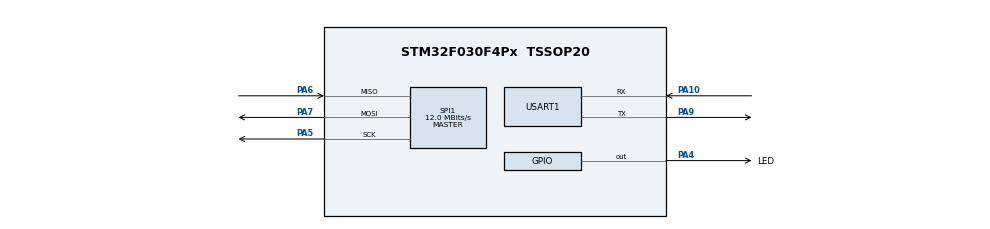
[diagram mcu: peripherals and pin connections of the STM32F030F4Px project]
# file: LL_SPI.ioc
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Mcu.Family=STM32F0
Mcu.Name=STM32F030F4Px
Mcu.Package=TSSOP20
PA10.Mode=Asynchronous
PA10.Signal=USART1_RX
PA13.Mode=Serial_Wire
PA13.Signal=SYS_SWDIO
PA14.Mode=Serial_Wire
PA14.Signal=SYS_SWCLK
PA4.GPIO_Label=LED
PA4.Signal=GPIO_Output
PA5.Mode=Full_Duplex_Master
PA5.Signal=SPI1_SCK
PA6.Mode=Full_Duplex_Master
PA6.Signal=SPI1_MISO
PA7.Mode=Full_Duplex_Master
PA7.Signal=SPI1_MOSI
PA9.Mode=Asynchronous
PA9.Signal=USART1_TX
PF0-OSC_IN.Mode=HSE-External-Oscillator
PF0-OSC_IN.Signal=RCC_OSC_IN
PF1-OSC_OUT.Mode=HSE-External-Oscillator
PF1-OSC_OUT.Signal=RCC_OSC_OUT
ProjectManager.HeapSize=0x200
ProjectManager.StackSize=0x400
ProjectManager.TargetToolchain=EWARM
RCC.AHBFreq_Value=48000000
RCC.APB1Freq_Value=48000000
RCC.APB1TimFreq_Value=48000000
RCC.HCLKFreq_Value=48000000
RCC.PLLMUL=RCC_PLL_MUL12
RCC.SYSCLKFreq_VALUE=48000000
RCC.SYSCLKSource=RCC_SYSCLKSOURCE_PLLCLK
SPI1.BaudRatePrescaler=SPI_BAUDRATEPRESCALER_4
SPI1.CLKPhase=SPI_PHASE_2EDGE
SPI1.CLKPolarity=SPI_POLARITY_HIGH
SPI1.CalculateBaudRate=12.0 MBits/s
SPI1.DataSize=SPI_DATASIZE_16BIT
SPI1.Direction=SPI_DIRECTION_2LINES
SPI1.Mode=SPI_MODE_MASTER
SPI1.VirtualType=VM_MASTER
USART1.VirtualMode-Asynchronous=VM_ASYNC
board=LL_SPI

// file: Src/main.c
/**
  ******************************************************************************
  * @file           : main.c
  * @brief          : Main program body
  ******************************************************************************
  ** This notice applies to any and all portions of this file
  * that are not between comment pairs USER CODE BEGIN and
  * USER CODE END. Other portions of this file, whether
  * inserted by the user or by software development tools
  * are owned by their respective copyright owners.
  *
  * COPYRIGHT(c) 2018 STMicroelectronics
  *
  * Redistribution and use in source and binary forms, with or without modification,
  * are permitted provided that the following conditions are met:
  *   1. Redistributions of source code must retain the above copyright notice,
  *      this list of conditions and the following disclaimer.
  *   2. Redistributions in binary form must reproduce the above copyright notice,
  *      this list of conditions and the following disclaimer in the documentation
  *      and/or other materials provided with the distribution.
  *   3. Neither the name of STMicroelectronics nor the names of its contributors
  *      may be used to endorse or promote products derived from this software
  *      without specific prior written permission.
  *
  * THIS SOFTWARE IS PROVIDED BY THE COPYRIGHT HOLDERS AND CONTRIBUTORS "AS IS"
  * AND ANY EXPRESS OR IMPLIED WARRANTIES, INCLUDING, BUT NOT LIMITED TO, THE
  * IMPLIED WARRANTIES OF MERCHANTABILITY AND FITNESS FOR A PARTICULAR PURPOSE ARE
  * DISCLAIMED. IN NO EVENT SHALL THE COPYRIGHT HOLDER OR CONTRIBUTORS BE LIABLE
  * FOR ANY DIRECT, INDIRECT, INCIDENTAL, SPECIAL, EXEMPLARY, OR CONSEQUENTIAL
  * DAMAGES (INCLUDING, BUT NOT LIMITED TO, PROCUREMENT OF SUBSTITUTE GOODS OR
  * SERVICES; LOSS OF USE, DATA, OR PROFITS; OR BUSINESS INTERRUPTION) HOWEVER
  * CAUSED AND ON ANY THEORY OF LIABILITY, WHETHER IN CONTRACT, STRICT LIABILITY,
  * OR TORT (INCLUDING NEGLIGENCE OR OTHERWISE) ARISING IN ANY WAY OUT OF THE USE
  * OF THIS SOFTWARE, EVEN IF ADVISED OF THE POSSIBILITY OF SUCH DAMAGE.
  *
  ******************************************************************************
  */
#include "main.h"

/* USER CODE BEGIN PV */
/* Private variables ---------------------------------------------------------*/

/* USER CODE END PV */

static void LL_Init(void);
void SystemClock_Config(void);
static void MX_GPIO_Init(void);
static void MX_USART1_UART_Init(void);
static void MX_SPI1_Init(void);

/* USER CODE BEGIN PFP */
/* Private function prototypes -----------------------------------------------*/

/* USER CODE END PFP */

int main(void)
{

  /* MCU Configuration----------------------------------------------------------*/

  /* Reset of all peripherals, Initializes the Flash interface and the Systick. */
  LL_Init();

  /* Configure the system clock */
  SystemClock_Config();

  /* Initialize all configured peripherals */
  MX_GPIO_Init();
  MX_USART1_UART_Init();
  MX_SPI1_Init();
  /* USER CODE BEGIN 2 */
  if( LL_SPI_IsEnabled(SPI1)==0 )
     {  LL_SPI_Enable(SPI1); }

  /* USER CODE END 2 */

  /* Infinite loop */
  while (1)
  {

  /* USER CODE BEGIN 3 */
    if(LL_SPI_IsActiveFlag_TXE(SPI1)==1)
      LL_mDelay(1000);
      LL_SPI_TransmitData16(SPI1,0x1995);

  }
  /* USER CODE END 3 */

}

static void LL_Init(void)
{

  LL_APB1_GRP2_EnableClock(LL_APB1_GRP2_PERIPH_SYSCFG);

  /* System interrupt init*/
  /* SVC_IRQn interrupt configuration */
  NVIC_SetPriority(SVC_IRQn, 0);
  /* PendSV_IRQn interrupt configuration */
  NVIC_SetPriority(PendSV_IRQn, 0);
  /* SysTick_IRQn interrupt configuration */
  NVIC_SetPriority(SysTick_IRQn, 0);

}

void SystemClock_Config(void)
{

  LL_FLASH_SetLatency(LL_FLASH_LATENCY_1);

  if(LL_FLASH_GetLatency() != LL_FLASH_LATENCY_1)
  {
  Error_Handler();
  }
  LL_RCC_HSI_Enable();

   /* Wait till HSI is ready */
  while(LL_RCC_HSI_IsReady() != 1)
  {

  }
  LL_RCC_HSI_SetCalibTrimming(16);

  LL_RCC_PLL_ConfigDomain_SYS(LL_RCC_PLLSOURCE_HSI_DIV_2, LL_RCC_PLL_MUL_12);

  LL_RCC_PLL_Enable();

   /* Wait till PLL is ready */
  while(LL_RCC_PLL_IsReady() != 1)
  {

  }
  LL_RCC_SetAHBPrescaler(LL_RCC_SYSCLK_DIV_1);

  LL_RCC_SetAPB1Prescaler(LL_RCC_APB1_DIV_1);

  LL_RCC_SetSysClkSource(LL_RCC_SYS_CLKSOURCE_PLL);

   /* Wait till System clock is ready */
  while(LL_RCC_GetSysClkSource() != LL_RCC_SYS_CLKSOURCE_STATUS_PLL)
  {

  }
  LL_Init1msTick(48000000);

  LL_SYSTICK_SetClkSource(LL_SYSTICK_CLKSOURCE_HCLK);

  LL_SetSystemCoreClock(48000000);

  LL_RCC_SetUSARTClockSource(LL_RCC_USART1_CLKSOURCE_PCLK1);

  /* SysTick_IRQn interrupt configuration */
  NVIC_SetPriority(SysTick_IRQn, 0);
}

/* SPI1 init function */
static void MX_SPI1_Init(void)
{

  LL_SPI_InitTypeDef SPI_InitStruct;

  LL_GPIO_InitTypeDef GPIO_InitStruct;

  /* Peripheral clock enable */
  LL_APB1_GRP2_EnableClock(LL_APB1_GRP2_PERIPH_SPI1);

  /**SPI1 GPIO Configuration
  PA5   ------> SPI1_SCK
  PA6   ------> SPI1_MISO
  PA7   ------> SPI1_MOSI
  */
  GPIO_InitStruct.Pin = LL_GPIO_PIN_5;
  GPIO_InitStruct.Mode = LL_GPIO_MODE_ALTERNATE;
  GPIO_InitStruct.Speed = LL_GPIO_SPEED_FREQ_HIGH;
  GPIO_InitStruct.OutputType = LL_GPIO_OUTPUT_PUSHPULL;
  GPIO_InitStruct.Pull = LL_GPIO_PULL_NO;
  GPIO_InitStruct.Alternate = LL_GPIO_AF_0;
  LL_GPIO_Init(GPIOA, &GPIO_InitStruct);

  GPIO_InitStruct.Pin = LL_GPIO_PIN_6;
  GPIO_InitStruct.Mode = LL_GPIO_MODE_ALTERNATE;
  GPIO_InitStruct.Speed = LL_GPIO_SPEED_FREQ_HIGH;
  GPIO_InitStruct.OutputType = LL_GPIO_OUTPUT_PUSHPULL;
  GPIO_InitStruct.Pull = LL_GPIO_PULL_NO;
  GPIO_InitStruct.Alternate = LL_GPIO_AF_0;
  LL_GPIO_Init(GPIOA, &GPIO_InitStruct);

  GPIO_InitStruct.Pin = LL_GPIO_PIN_7;
  GPIO_InitStruct.Mode = LL_GPIO_MODE_ALTERNATE;
  GPIO_InitStruct.Speed = LL_GPIO_SPEED_FREQ_HIGH;
  GPIO_InitStruct.OutputType = LL_GPIO_OUTPUT_PUSHPULL;
  GPIO_InitStruct.Pull = LL_GPIO_PULL_NO;
  GPIO_InitStruct.Alternate = LL_GPIO_AF_0;
  LL_GPIO_Init(GPIOA, &GPIO_InitStruct);

  /* SPI1 parameter configuration*/
  SPI_InitStruct.TransferDirection = LL_SPI_FULL_DUPLEX;
  SPI_InitStruct.Mode = LL_SPI_MODE_MASTER;
  SPI_InitStruct.DataWidth = LL_SPI_DATAWIDTH_16BIT;
  SPI_InitStruct.ClockPolarity = LL_SPI_POLARITY_HIGH;
  SPI_InitStruct.ClockPhase = LL_SPI_PHASE_2EDGE;
  SPI_InitStruct.NSS = LL_SPI_NSS_SOFT;
  SPI_InitStruct.BaudRate = LL_SPI_BAUDRATEPRESCALER_DIV4;
  SPI_InitStruct.BitOrder = LL_SPI_MSB_FIRST;
  SPI_InitStruct.CRCCalculation = LL_SPI_CRCCALCULATION_DISABLE;
  SPI_InitStruct.CRCPoly = 7;
  LL_SPI_Init(SPI1, &SPI_InitStruct);

  LL_SPI_SetStandard(SPI1, LL_SPI_PROTOCOL_MOTOROLA);

  LL_SPI_DisableNSSPulseMgt(SPI1);

}

/* USART1 init function */
static void MX_USART1_UART_Init(void)
{

  LL_USART_InitTypeDef USART_InitStruct;

  LL_GPIO_InitTypeDef GPIO_InitStruct;

  /* Peripheral clock enable */
  LL_APB1_GRP2_EnableClock(LL_APB1_GRP2_PERIPH_USART1);

  /**USART1 GPIO Configuration
  PA9   ------> USART1_TX
  PA10   ------> USART1_RX
  */
  GPIO_InitStruct.Pin = LL_GPIO_PIN_9;
  GPIO_InitStruct.Mode = LL_GPIO_MODE_ALTERNATE;
  GPIO_InitStruct.Speed = LL_GPIO_SPEED_FREQ_HIGH;
  GPIO_InitStruct.OutputType = LL_GPIO_OUTPUT_PUSHPULL;
  GPIO_InitStruct.Pull = LL_GPIO_PULL_NO;
  GPIO_InitStruct.Alternate = LL_GPIO_AF_1;
  LL_GPIO_Init(GPIOA, &GPIO_InitStruct);

  GPIO_InitStruct.Pin = LL_GPIO_PIN_10;
  GPIO_InitStruct.Mode = LL_GPIO_MODE_ALTERNATE;
  GPIO_InitStruct.Speed = LL_GPIO_SPEED_FREQ_HIGH;
  GPIO_InitStruct.OutputType = LL_GPIO_OUTPUT_PUSHPULL;
  GPIO_InitStruct.Pull = LL_GPIO_PULL_NO;
  GPIO_InitStruct.Alternate = LL_GPIO_AF_1;
  LL_GPIO_Init(GPIOA, &GPIO_InitStruct);

  USART_InitStruct.BaudRate = 38400;
  USART_InitStruct.DataWidth = LL_USART_DATAWIDTH_8B;
  USART_InitStruct.StopBits = LL_USART_STOPBITS_1;
  USART_InitStruct.Parity = LL_USART_PARITY_NONE;
  USART_InitStruct.TransferDirection = LL_USART_DIRECTION_TX_RX;
  USART_InitStruct.HardwareFlowControl = LL_USART_HWCONTROL_NONE;
  USART_InitStruct.OverSampling = LL_USART_OVERSAMPLING_16;
  LL_USART_Init(USART1, &USART_InitStruct);

  LL_USART_DisableIT_CTS(USART1);

  LL_USART_DisableOverrunDetect(USART1);

  LL_USART_ConfigAsyncMode(USART1);

  LL_USART_Enable(USART1);

}

/** Configure pins as
        * Analog
        * Input
        * Output
        * EVENT_OUT
        * EXTI
*/
static void MX_GPIO_Init(void)
{

  LL_GPIO_InitTypeDef GPIO_InitStruct;

  /* GPIO Ports Clock Enable */
  LL_AHB1_GRP1_EnableClock(LL_AHB1_GRP1_PERIPH_GPIOF);
  LL_AHB1_GRP1_EnableClock(LL_AHB1_GRP1_PERIPH_GPIOA);

  /**/
  LL_GPIO_ResetOutputPin(LED_GPIO_Port, LED_Pin);

  /**/
  GPIO_InitStruct.Pin = LED_Pin;
  GPIO_InitStruct.Mode = LL_GPIO_MODE_OUTPUT;
  GPIO_InitStruct.Speed = LL_GPIO_SPEED_FREQ_LOW;
  GPIO_InitStruct.OutputType = LL_GPIO_OUTPUT_PUSHPULL;
  GPIO_InitStruct.Pull = LL_GPIO_PULL_NO;
  LL_GPIO_Init(LED_GPIO_Port, &GPIO_InitStruct);

}

void _Error_Handler(char *file, int line)
{
  while(1)
  {
  }
}

/************************ (C) COPYRIGHT STMicroelectronics *****END OF FILE****/
